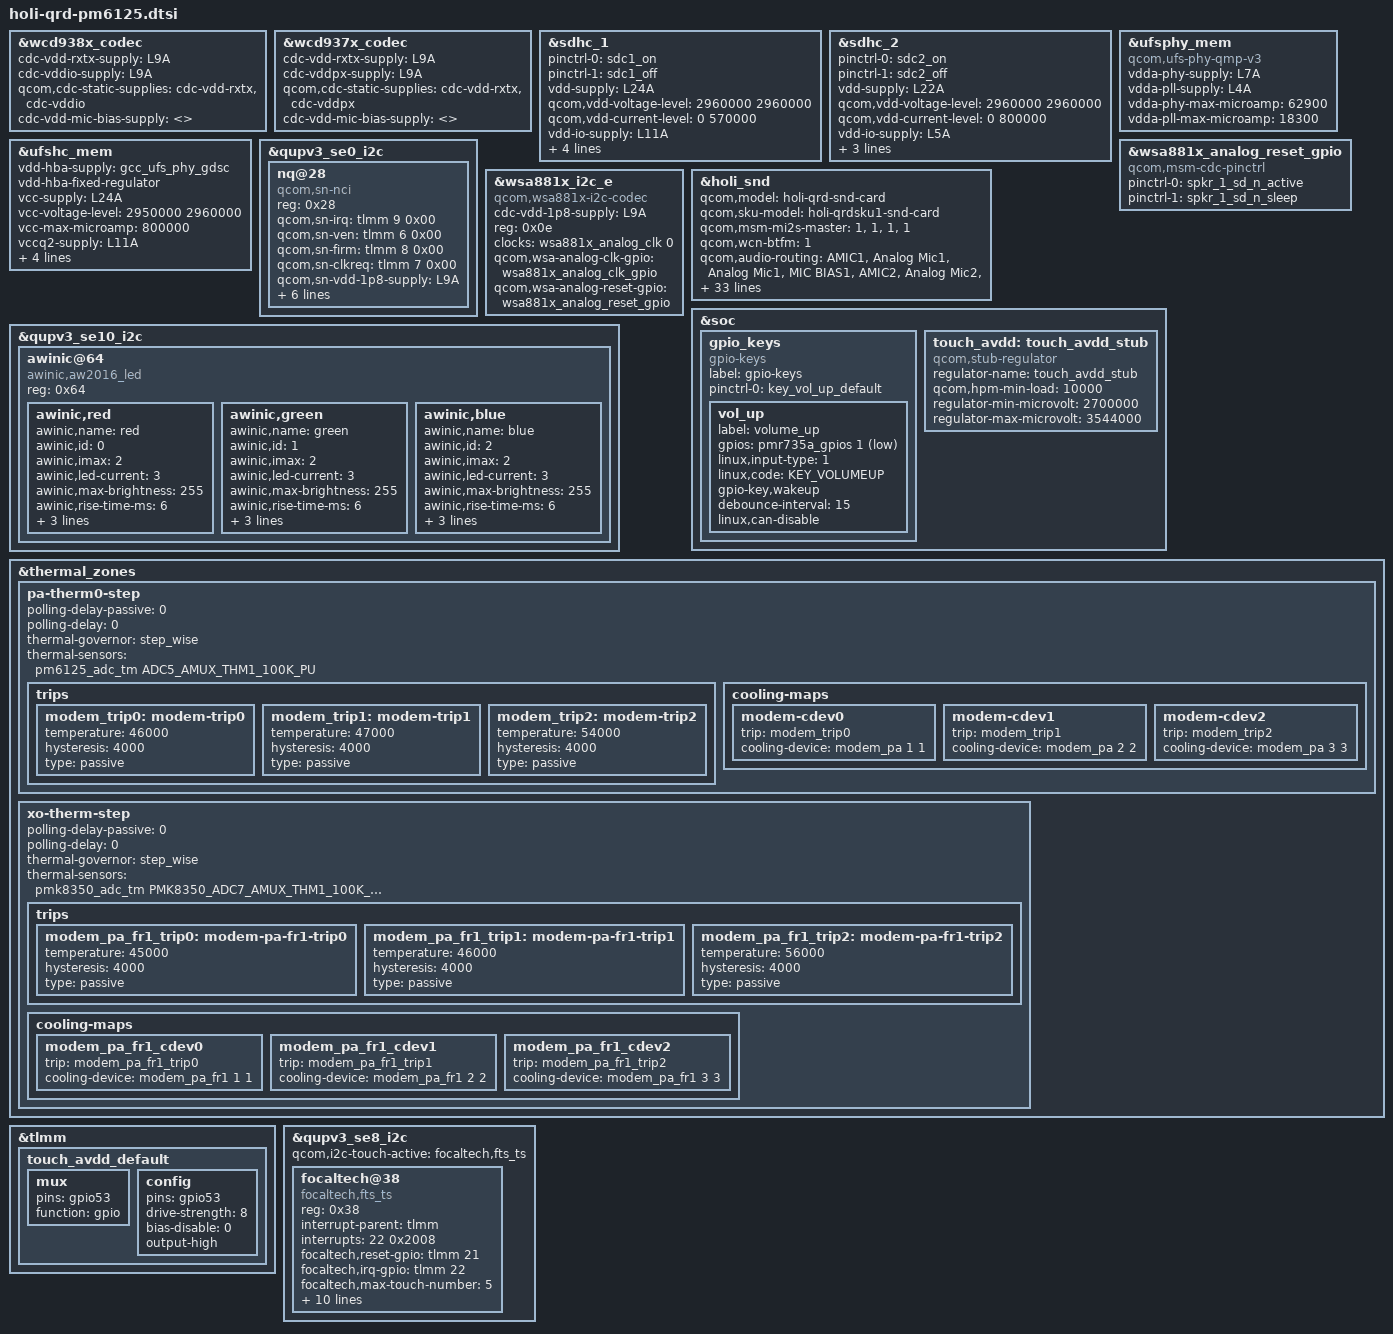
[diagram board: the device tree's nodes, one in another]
#include "holi-audio-overlay.dtsi"
#include <dt-bindings/gpio/gpio.h>
#include <dt-bindings/input/linux-event-codes.h>
#include "holi-pmic-overlay-pm6125.dtsi"
#include "holi-thermal-overlay-pm6125.dtsi"
#include "holi-sde-display-qrd-pm6125.dtsi"
#include "holi-camera-pm6125-overlay.dtsi"

&wcd938x_codec {
	cdc-vdd-rxtx-supply = <&L9A>;
	cdc-vddio-supply = <&L9A>;
	qcom,cdc-static-supplies = "cdc-vdd-rxtx",
				   "cdc-vddio";
	/*
	 * Overriding cdc-vdd-mic-bias-supply to dummy value
	 * to avoid compilation errors as BOB is not definied
	 * for pm6125
	 */
	cdc-vdd-mic-bias-supply = <>;
};

&wcd937x_codec {
	status = "ok";
	cdc-vdd-rxtx-supply = <&L9A>;
	cdc-vddpx-supply = <&L9A>;
	qcom,cdc-static-supplies = "cdc-vdd-rxtx",
				   "cdc-vddpx";
	/*
	 * Overriding cdc-vdd-mic-bias-supply to dummy value
	 * to avoid compilation errors as BOB is not definied
	 * for pm6125
	 */
	cdc-vdd-mic-bias-supply = <>;
};

&sdhc_1 {
	status = "ok";

	pinctrl-names = "default", "sleep";
	pinctrl-0 = <&sdc1_on>;
	pinctrl-1 = <&sdc1_off>;

	vdd-supply = <&L24A>;
	qcom,vdd-voltage-level = <2960000 2960000>;
	qcom,vdd-current-level = <0 570000>;

	vdd-io-supply = <&L11A>;
	qcom,vdd-io-always-on;
	qcom,vdd-io-lpm-sup;
	qcom,vdd-io-voltage-level = <1800000 1800000>;
	qcom,vdd-io-current-level = <0 325000>;
};

&sdhc_2 {
	status = "ok";

	pinctrl-names = "default", "sleep";
	pinctrl-0 = <&sdc2_on>;
	pinctrl-1 = <&sdc2_off>;

	vdd-supply = <&L22A>;
	qcom,vdd-voltage-level = <2960000 2960000>;
	qcom,vdd-current-level = <0 800000>;

	vdd-io-supply = <&L5A>;
	qcom,vdd-io-voltage-level = <1800000 2960000>;
	qcom,vdd-io-current-level = <0 22000>;

	cd-gpios = <&tlmm 94 GPIO_ACTIVE_LOW>;
};

&ufsphy_mem {
	compatible = "qcom,ufs-phy-qmp-v3";

	vdda-phy-supply = <&L7A>;
	vdda-pll-supply = <&L4A>;
	vdda-phy-max-microamp = <62900>;
	vdda-pll-max-microamp = <18300>;

	status = "ok";
};

&ufshc_mem {
	vdd-hba-supply = <&gcc_ufs_phy_gdsc>;
	vdd-hba-fixed-regulator;

	vcc-supply = <&L24A>;
	vcc-voltage-level = <2950000 2960000>;
	vcc-max-microamp = <800000>;

	vccq2-supply = <&L11A>;
	vccq2-max-microamp = <800000>;
	vccq2-voltage-level = <1800000 1800000>;

	qcom,vddp-ref-clk-supply = <&L4A>;
	qcom,vddp-ref-clk-max-microamp = <100>;

	status = "ok";
};

&qupv3_se0_i2c {
	status = "ok";
	#address-cells = <1>;
	#size-cells = <0>;
	nq@28 {
		compatible = "qcom,sn-nci";
		reg = <0x28>;
		qcom,sn-irq = <&tlmm 9 0x00>;
		qcom,sn-ven = <&tlmm 6 0x00>;
		qcom,sn-firm = <&tlmm 8 0x00>;
		qcom,sn-clkreq = <&tlmm 7 0x00>;
		qcom,sn-vdd-1p8-supply = <&L9A>;
		qcom,sn-vdd-1p8-voltage = <1800000 1800000>;
		qcom,sn-vdd-1p8-current = <157000>;
		interrupt-parent = <&tlmm>;
		interrupts = <9 0>;
		interrupt-names = "nfc_irq";
		pinctrl-names = "nfc_active", "nfc_suspend";
		pinctrl-0 = <&nfc_int_active &nfc_enable_active>;
		pinctrl-1 = <&nfc_int_suspend &nfc_enable_suspend>;
	};
};

&wsa881x_analog_reset_gpio {
	compatible = "qcom,msm-cdc-pinctrl";
	pinctrl-names = "aud_active", "aud_sleep";
	pinctrl-0 = <&spkr_1_sd_n_active>;
	pinctrl-1 = <&spkr_1_sd_n_sleep>;
};

&wsa881x_i2c_e {
	status = "ok";
	cdc-vdd-1p8-supply = <&L9A>;
	compatible = "qcom,wsa881x-i2c-codec";
	reg = <0x0e>;
	clock-names = "wsa_mclk";
	clocks = <&wsa881x_analog_clk 0>;
	qcom,wsa-analog-clk-gpio = <&wsa881x_analog_clk_gpio>;
	qcom,wsa-analog-reset-gpio = <&wsa881x_analog_reset_gpio>;
};

&holi_snd {
	qcom,model = "holi-qrd-snd-card";
	qcom,sku-model = "holi-qrdsku1-snd-card";
	qcom,msm-mi2s-master = <1>, <1>, <1>, <1>;
	qcom,wcn-btfm = <1>;
	qcom,audio-routing =
		"AMIC1", "Analog Mic1",
		"Analog Mic1", "MIC BIAS1",
		"AMIC2", "Analog Mic2",
		"Analog Mic2", "MIC BIAS2",
		"AMIC3", "Analog Mic3",
		"Analog Mic3", "MIC BIAS3",
		"AMIC4", "Analog Mic4",
		"Analog Mic4", "MIC BIAS3",
		"TX DMIC0", "Digital Mic0",
		"TX DMIC0", "MIC BIAS1",
		"TX DMIC1", "Digital Mic1",
		"TX DMIC1", "MIC BIAS1",
		"TX DMIC2", "Digital Mic2",
		"TX DMIC2", "MIC BIAS3",
		"TX DMIC3", "Digital Mic3",
		"TX DMIC3", "MIC BIAS3",
		"IN1_HPHL", "HPHL_OUT",
		"IN2_HPHR", "HPHR_OUT",
		"IN3_AUX", "AUX_OUT",
		"RX_TX DEC0_INP", "TX DEC0 MUX",
		"RX_TX DEC1_INP", "TX DEC1 MUX",
		"RX_TX DEC2_INP", "TX DEC2 MUX",
		"RX_TX DEC3_INP", "TX DEC3 MUX",
		"SpkrMono WSA_IN", "AUX",
		"TX SWR_INPUT", "WCD_TX_OUTPUT",
		"VA SWR_INPUT", "VA_SWR_CLK",
		"VA SWR_INPUT", "WCD_TX_OUTPUT",
		"VA_AIF1 CAP", "VA_SWR_CLK",
		"VA_AIF2 CAP", "VA_SWR_CLK",
		"VA_AIF3 CAP", "VA_SWR_CLK",
		"VA DMIC0", "Digital Mic0",
		"VA DMIC1", "Digital Mic1",
		"VA DMIC2", "Digital Mic2",
		"VA DMIC3", "Digital Mic3",
		"VA DMIC4", "Digital Mic4",
		"VA DMIC5", "Digital Mic5",
		"VA DMIC0", "VA MIC BIAS1",
		"VA DMIC1", "VA MIC BIAS1",
		"VA DMIC2", "VA MIC BIAS3",
		"VA DMIC3", "VA MIC BIAS3";
	qcom,msm-mbhc-hphl-swh = <1>;
	qcom,msm-mbhc-gnd-swh = <1>;
	qcom,cdc-dmic01-gpios = <&cdc_dmic01_gpios>;
	qcom,cdc-dmic23-gpios = <&cdc_dmic23_gpios>;
	asoc-codec  = <&stub_codec>, <&bolero>,
		      <&wcd937x_codec>, <&wsa881x_i2c_e>;
	asoc-codec-names = "msm-stub-codec.1", "bolero_codec",
			   "wcd937x_codec", "wsa-codec0";
	qcom,msm_audio_ssr_devs = <&audio_apr>, <&q6core>, <&lpi_tlmm>,
				  <&bolero>;
};

&soc {
	gpio_keys {
		compatible = "gpio-keys";
		label = "gpio-keys";

		pinctrl-names = "default";
		pinctrl-0 = <&key_vol_up_default>;

		vol_up {
			label = "volume_up";
			gpios = <&pmr735a_gpios 1 GPIO_ACTIVE_LOW>;
			linux,input-type = <1>;
			linux,code = <KEY_VOLUMEUP>;
			gpio-key,wakeup;
			debounce-interval = <15>;
			linux,can-disable;
		};
	};
};

#include "holi-camera-sensor-pm6125-mtp.dtsi"

&qupv3_se10_i2c {
	awinic@64 {
		compatible = "awinic,aw2016_led";
		reg = <0x64>;

		awinic,red {
			awinic,name = "red";
			awinic,id = <0>;
			awinic,imax = <2>;
			awinic,led-current = <3>;
			awinic,max-brightness = <255>;
			awinic,rise-time-ms = <6>;
			awinic,hold-time-ms = <0>;
			awinic,fall-time-ms = <6>;
			awinic,off-time-ms = <4>;
		};

		awinic,green {
			awinic,name = "green";
			awinic,id = <1>;
			awinic,imax = <2>;
			awinic,led-current = <3>;
			awinic,max-brightness = <255>;
			awinic,rise-time-ms = <6>;
			awinic,hold-time-ms = <0>;
			awinic,fall-time-ms = <6>;
			awinic,off-time-ms = <4>;
		};

		awinic,blue {
			awinic,name = "blue";
			awinic,id = <2>;
			awinic,imax = <2>;
			awinic,led-current = <3>;
			awinic,max-brightness = <255>;
			awinic,rise-time-ms = <6>;
			awinic,hold-time-ms = <0>;
			awinic,fall-time-ms = <6>;
			awinic,off-time-ms = <4>;
		};

	};
};

&thermal_zones {
	pa-therm0-step {
		polling-delay-passive = <0>;
		polling-delay = <0>;
		thermal-governor = "step_wise";
		thermal-sensors = <&pm6125_adc_tm ADC5_AMUX_THM1_100K_PU>;
		trips {
			modem_trip0: modem-trip0 {
				temperature = <46000>;
				hysteresis = <4000>;
				type = "passive";
			};

			modem_trip1: modem-trip1 {
				temperature = <47000>;
				hysteresis = <4000>;
				type = "passive";
			};

			modem_trip2: modem-trip2 {
				temperature = <54000>;
				hysteresis = <4000>;
				type = "passive";
			};
		};

		cooling-maps {
			modem-cdev0 {
				trip = <&modem_trip0>;
				cooling-device = <&modem_pa 1 1>;
			};

			modem-cdev1 {
				trip = <&modem_trip1>;
				cooling-device = <&modem_pa 2 2>;
			};

			modem-cdev2 {
				trip = <&modem_trip2>;
				cooling-device = <&modem_pa 3 3>;
			};
		};
	};

	xo-therm-step {
		polling-delay-passive = <0>;
		polling-delay = <0>;
		thermal-governor = "step_wise";
		thermal-sensors = <&pmk8350_adc_tm PMK8350_ADC7_AMUX_THM1_100K_PU>;
		trips {
			modem_pa_fr1_trip0: modem-pa-fr1-trip0 {
				temperature = <45000>;
				hysteresis = <4000>;
				type = "passive";
			};

			modem_pa_fr1_trip1: modem-pa-fr1-trip1 {
				temperature = <46000>;
				hysteresis = <4000>;
				type = "passive";
			};

			modem_pa_fr1_trip2: modem-pa-fr1-trip2 {
				temperature = <56000>;
				hysteresis = <4000>;
				type = "passive";
			};
		};

		cooling-maps {
			modem_pa_fr1_cdev0 {
				trip = <&modem_pa_fr1_trip0>;
				cooling-device = <&modem_pa_fr1 1 1>;
			};

			modem_pa_fr1_cdev1 {
				trip = <&modem_pa_fr1_trip1>;
				cooling-device = <&modem_pa_fr1 2 2>;
			};

			modem_pa_fr1_cdev2 {
				trip = <&modem_pa_fr1_trip2>;
				cooling-device = <&modem_pa_fr1 3 3>;
			};
		};
	};
};

&tlmm {
	touch_avdd_default: touch_avdd_default {
		mux {
			pins = "gpio53";
			function = "gpio";
		};

		config {
			pins = "gpio53";
			drive-strength = <8>;
			bias-disable = <0>;
			output-high;
		};
	};
};

&soc {
	touch_avdd: touch_avdd_stub {
		/*
		 * Touch eLDO controlled by gpio#53 is always ON.
		 * Using dummy regulator.
		 */
		compatible = "qcom,stub-regulator";
		regulator-name = "touch_avdd_stub";
		qcom,hpm-min-load = <10000>;
		regulator-min-microvolt = <2700000>;
		regulator-max-microvolt = <3544000>;
	};
};

&qupv3_se8_i2c {
	#address-cells = <1>;
	#size-cells = <0>;

	status = "ok";
	qcom,i2c-touch-active = "focaltech,fts_ts";

	focaltech@38 {
		compatible = "focaltech,fts_ts";
		reg = <0x38>;
		interrupt-parent = <&tlmm>;
		interrupts = <22 0x2008>;
		focaltech,reset-gpio = <&tlmm 21 0x00>;
		focaltech,irq-gpio = <&tlmm 22 0x2008>;
		focaltech,max-touch-number = <5>;
		focaltech,display-coords = <0 0 1080 2340>;

		vcc_i2c-supply = <&L9A>;
		vdd-supply = <&touch_avdd>;

		pinctrl-names = "pmx_ts_active", "pmx_ts_suspend",
				"pmx_ts_release";
		pinctrl-0 = <&ts_active>;
		pinctrl-1 = <&ts_int_suspend &ts_reset_suspend>;
		pinctrl-2 = <&pmx_ts_release>;

		panel = <&dsi_r66451_amoled_90hz_cmd
			 &dsi_r66451_amoled_90hz_video
			 &dsi_r66451_amoled_cmd &dsi_r66451_amoled_video>;
	};
};
